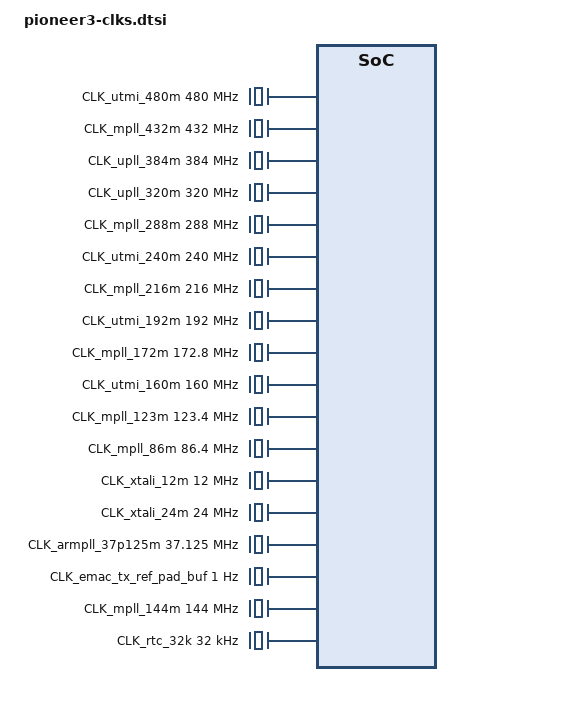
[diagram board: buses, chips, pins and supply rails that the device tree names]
/*
* pioneer3-clks.dtsi- Sigmastar
*
* Copyright (c) [2019~2020] SigmaStar Technology.
*
*
* This software is licensed under the terms of the GNU General Public
* License version 2, as published by the Free Software Foundation, and
* may be copied, distributed, and modified under those terms.
*
* This program is distributed in the hope that it will be useful,
* but WITHOUT ANY WARRANTY; without even the implied warranty of
* MERCHANTABILITY or FITNESS FOR A PARTICULAR PURPOSE.  See the
* GNU General Public License version 2 for more details.
*
*/

/* generated by CLK_DT_GEN_5.1 */
/* CLK FILENAME: Pioneer3\Pioneer3_Clock_Table_sw.xls */
/* REG FILENAME: Pioneer3\Pioneer3_reg_CLKGEN.xls, Pioneer3\Pioneer3_reg_pm_sleep.xls, Pioneer3\Pioneer3_reg_block.xls, Pioneer3\Pioneer3_reg_chiptop.xls */

CLK_VOID: CLK_VOID {
    #clock-cells = <0>;
    compatible = "fixed-clock";
    clock-frequency = <1>;
};

CLK_utmi_480m: CLK_utmi_480m {
    #clock-cells = <0>;
    compatible = "fixed-clock";
    clock-frequency = <480000000>;
};

CLK_mpll_432m: CLK_mpll_432m {
    #clock-cells = <0>;
    compatible = "fixed-clock";
    clock-frequency = <432000000>;
};

CLK_upll_384m: CLK_upll_384m {
    #clock-cells = <0>;
    compatible = "fixed-clock";
    clock-frequency = <384000000>;
};

CLK_upll_320m: CLK_upll_320m {
    #clock-cells = <0>;
    compatible = "fixed-clock";
    clock-frequency = <320000000>;
};

CLK_mpll_288m: CLK_mpll_288m {
    #clock-cells = <0>;
    compatible = "fixed-clock";
    clock-frequency = <288000000>;
};

CLK_utmi_240m: CLK_utmi_240m {
    #clock-cells = <0>;
    compatible = "fixed-clock";
    clock-frequency = <240000000>;
};

CLK_mpll_216m: CLK_mpll_216m {
    #clock-cells = <0>;
    compatible = "fixed-clock";
    clock-frequency = <216000000>;
};

CLK_utmi_192m: CLK_utmi_192m {
    #clock-cells = <0>;
    compatible = "fixed-clock";
    clock-frequency = <192000000>;
};

CLK_mpll_172m: CLK_mpll_172m {
    #clock-cells = <0>;
    compatible = "fixed-clock";
    clock-frequency = <172800000>;
};

CLK_utmi_160m: CLK_utmi_160m {
    #clock-cells = <0>;
    compatible = "fixed-clock";
    clock-frequency = <160000000>;
};

CLK_mpll_123m: CLK_mpll_123m {
    #clock-cells = <0>;
    compatible = "fixed-clock";
    clock-frequency = <123400000>;
};

CLK_mpll_86m: CLK_mpll_86m {
    #clock-cells = <0>;
    compatible = "fixed-clock";
    clock-frequency = <86400000>;
};

CLK_mpll_288m_div2: CLK_mpll_288m_div2 {
    #clock-cells = <0>;
    compatible = "fixed-factor-clock";
    clocks = <&CLK_mpll_288m>;
    clock-div = <2>;
    clock-mult = <1>;
};

CLK_mpll_288m_div4: CLK_mpll_288m_div4 {
    #clock-cells = <0>;
    compatible = "fixed-factor-clock";
    clocks = <&CLK_mpll_288m>;
    clock-div = <4>;
    clock-mult = <1>;
};

CLK_mpll_288m_div8: CLK_mpll_288m_div8 {
    #clock-cells = <0>;
    compatible = "fixed-factor-clock";
    clocks = <&CLK_mpll_288m>;
    clock-div = <8>;
    clock-mult = <1>;
};

CLK_mpll_288m_div32: CLK_mpll_288m_div32 {
    #clock-cells = <0>;
    compatible = "fixed-factor-clock";
    clocks = <&CLK_mpll_288m>;
    clock-div = <32>;
    clock-mult = <1>;
};

CLK_mpll_216m_div2: CLK_mpll_216m_div2 {
    #clock-cells = <0>;
    compatible = "fixed-factor-clock";
    clocks = <&CLK_mpll_216m>;
    clock-div = <2>;
    clock-mult = <1>;
};

CLK_mpll_216m_div4: CLK_mpll_216m_div4 {
    #clock-cells = <0>;
    compatible = "fixed-factor-clock";
    clocks = <&CLK_mpll_216m>;
    clock-div = <4>;
    clock-mult = <1>;
};

CLK_mpll_216m_div8: CLK_mpll_216m_div8 {
    #clock-cells = <0>;
    compatible = "fixed-factor-clock";
    clocks = <&CLK_mpll_216m>;
    clock-div = <8>;
    clock-mult = <1>;
};

CLK_mpll_123m_div2: CLK_mpll_123m_div2 {
    #clock-cells = <0>;
    compatible = "fixed-factor-clock";
    clocks = <&CLK_mpll_123m>;
    clock-div = <2>;
    clock-mult = <1>;
};

CLK_mpll_86m_div2: CLK_mpll_86m_div2 {
    #clock-cells = <0>;
    compatible = "fixed-factor-clock";
    clocks = <&CLK_mpll_86m>;
    clock-div = <2>;
    clock-mult = <1>;
};

CLK_mpll_86m_div4: CLK_mpll_86m_div4 {
    #clock-cells = <0>;
    compatible = "fixed-factor-clock";
    clocks = <&CLK_mpll_86m>;
    clock-div = <4>;
    clock-mult = <1>;
};

CLK_mpll_86m_div16: CLK_mpll_86m_div16 {
    #clock-cells = <0>;
    compatible = "fixed-factor-clock";
    clocks = <&CLK_mpll_86m>;
    clock-div = <16>;
    clock-mult = <1>;
};

CLK_utmi_192m_div4: CLK_utmi_192m_div4 {
    #clock-cells = <0>;
    compatible = "fixed-factor-clock";
    clocks = <&CLK_utmi_192m>;
    clock-div = <4>;
    clock-mult = <1>;
};

CLK_utmi_160m_div4: CLK_utmi_160m_div4 {
    #clock-cells = <0>;
    compatible = "fixed-factor-clock";
    clocks = <&CLK_utmi_160m>;
    clock-div = <4>;
    clock-mult = <1>;
};

CLK_utmi_160m_div5: CLK_utmi_160m_div5 {
    #clock-cells = <0>;
    compatible = "fixed-factor-clock";
    clocks = <&CLK_utmi_160m>;
    clock-div = <5>;
    clock-mult = <1>;
};

CLK_utmi_160m_div8: CLK_utmi_160m_div8 {
    #clock-cells = <0>;
    compatible = "fixed-factor-clock";
    clocks = <&CLK_utmi_160m>;
    clock-div = <8>;
    clock-mult = <1>;
};

CLK_xtali_12m: CLK_xtali_12m {
    #clock-cells = <0>;
    compatible = "fixed-clock";
    clock-frequency = <12000000>;
};

CLK_xtali_12m_div8: CLK_xtali_12m_div8 {
    #clock-cells = <0>;
    compatible = "fixed-factor-clock";
    clocks = <&CLK_xtali_12m>;
    clock-div = <8>;
    clock-mult = <1>;
};

CLK_xtali_12m_div16: CLK_xtali_12m_div16 {
    #clock-cells = <0>;
    compatible = "fixed-factor-clock";
    clocks = <&CLK_xtali_12m>;
    clock-div = <16>;
    clock-mult = <1>;
};

CLK_xtali_12m_div40: CLK_xtali_12m_div40 {
    #clock-cells = <0>;
    compatible = "fixed-factor-clock";
    clocks = <&CLK_xtali_12m>;
    clock-div = <40>;
    clock-mult = <1>;
};

CLK_xtali_12m_div64: CLK_xtali_12m_div64 {
    #clock-cells = <0>;
    compatible = "fixed-factor-clock";
    clocks = <&CLK_xtali_12m>;
    clock-div = <64>;
    clock-mult = <1>;
};

CLK_xtali_12m_div128: CLK_xtali_12m_div128 {
    #clock-cells = <0>;
    compatible = "fixed-factor-clock";
    clocks = <&CLK_xtali_12m>;
    clock-div = <128>;
    clock-mult = <1>;
};

CLK_xtali_24m: CLK_xtali_24m {
    #clock-cells = <0>;
    compatible = "fixed-clock";
    clock-frequency = <24000000>;
};

CLK_lpll_clk: CLK_lpll_clk {
    #clock-cells = <0>;
    compatible = "fixed-clock";
    clock-frequency = <288000000>;
};

CLK_lpll_clk_div2: CLK_lpll_clk_div2 {
    #clock-cells = <0>;
    compatible = "fixed-factor-clock";
    clocks = <&CLK_lpll_clk>;
    clock-div = <2>;
    clock-mult = <1>;
};

CLK_lpll_clk_div4: CLK_lpll_clk_div4 {
    #clock-cells = <0>;
    compatible = "fixed-factor-clock";
    clocks = <&CLK_lpll_clk>;
    clock-div = <4>;
    clock-mult = <1>;
};

CLK_lpll_clk_div8: CLK_lpll_clk_div8 {
    #clock-cells = <0>;
    compatible = "fixed-factor-clock";
    clocks = <&CLK_lpll_clk>;
    clock-div = <8>;
    clock-mult = <1>;
};

CLK_spi_synth_pll: CLK_spi_synth_pll {
    #clock-cells = <0>;
    compatible = "fixed-clock";
    clock-frequency = <104000000>;
};

CLK_fuart0_synth_out: CLK_fuart0_synth_out {
    #clock-cells = <0>;
    compatible = "fixed-clock";
    clock-frequency = <432000000>;
};

CLK_miu_p: CLK_miu_p {
    #clock-cells = <0>;
    compatible = "fixed-clock";
    clock-frequency = <266000000>;
};

CLK_mcu_p: CLK_mcu_p {
    #clock-cells = <0>;
    compatible = "fixed-clock";
    clock-frequency = <432000000>;
};

CLK_emac_testrx125_in_lan: CLK_emac_testrx125_in_lan {
    #clock-cells = <0>;
    compatible = "fixed-clock";
    clock-frequency = <125000000>;
};

CLK_armpll_37p125m: CLK_armpll_37p125m {
    #clock-cells = <0>;
    compatible = "fixed-clock";
    clock-frequency = <37125000>;
};

CLK_boot: CLK_boot {
    #clock-cells = <0>;
    compatible = "fixed-clock";
    clock-frequency = <12000000>;
};

CLK_dac_in: CLK_dac_in {
    #clock-cells = <0>;
    compatible = "fixed-clock";
    clock-frequency = <1>;
};

CLK_hdmi_p: CLK_hdmi_p {
    #clock-cells = <0>;
    compatible = "fixed-clock";
    clock-frequency = <1>;
};

CLK_emac_rx_in_buf: CLK_emac_rx_in_buf {
    #clock-cells = <0>;
    compatible = "fixed-clock";
    clock-frequency = <1>;
};

CLK_emac_mmi_rx_buf: CLK_emac_mmi_rx_buf {
    #clock-cells = <0>;
    compatible = "fixed-clock";
    clock-frequency = <1>;
};

CLK_emac_tx_ref_pad_buf: CLK_emac_tx_ref_pad_buf {
    #clock-cells = <0>;
    compatible = "fixed-clock";
    clock-frequency = <1>;
};

CLK_emac_tx_in_buf: CLK_emac_tx_in_buf {
    #clock-cells = <0>;
    compatible = "fixed-clock";
    clock-frequency = <1>;
};

CLK_emac_mmi_tx_buf: CLK_emac_mmi_tx_buf {
    #clock-cells = <0>;
    compatible = "fixed-clock";
    clock-frequency = <1>;
};

CLK_odclk_live_p: CLK_odclk_live_p {
    #clock-cells = <0>;
    compatible = "fixed-clock";
    clock-frequency = <1>;
};

CLK_miu_gop0_p: CLK_miu_gop0_p {
    #clock-cells = <0>;
    compatible = "fixed-clock";
    clock-frequency = <1>;
};

CLK_miu_gop1_p: CLK_miu_gop1_p {
    #clock-cells = <0>;
    compatible = "fixed-clock";
    clock-frequency = <1>;
};

CLK_sc_pixel_p: CLK_sc_pixel_p {
    #clock-cells = <0>;
    compatible = "fixed-clock";
    clock-frequency = <1>;
};

CLK_mipi_tx_dsi_p: CLK_mipi_tx_dsi_p {
    #clock-cells = <0>;
    compatible = "fixed-clock";
    clock-frequency = <1>;
};

CLK_miu_sc_gp_p_inv: CLK_miu_sc_gp_p_inv {
    #clock-cells = <0>;
    compatible = "fixed-clock";
    clock-frequency = <1>;
};

CLK_pad_sdio_clk_mux: CLK_pad_sdio_clk_mux {
    #clock-cells = <0>;
    compatible = "fixed-clock";
    clock-frequency = <1>;
};

CLK_mpll_144m: CLK_mpll_144m {
    #clock-cells = <0>;
    compatible = "fixed-clock";
    clock-frequency = <144000000>;
};

CLK_mpll_144m_div2: CLK_mpll_144m_div2 {
    #clock-cells = <0>;
    compatible = "fixed-factor-clock";
    clocks = <&CLK_mpll_144m>;
    clock-div = <2>;
    clock-mult = <1>;
};

CLK_mpll_144m_div4: CLK_mpll_144m_div4 {
    #clock-cells = <0>;
    compatible = "fixed-factor-clock";
    clocks = <&CLK_mpll_144m>;
    clock-div = <4>;
    clock-mult = <1>;
};

CLK_xtali_12m_div2: CLK_xtali_12m_div2 {
    #clock-cells = <0>;
    compatible = "fixed-factor-clock";
    clocks = <&CLK_xtali_12m>;
    clock-div = <2>;
    clock-mult = <1>;
};

CLK_xtali_12m_div4: CLK_xtali_12m_div4 {
    #clock-cells = <0>;
    compatible = "fixed-factor-clock";
    clocks = <&CLK_xtali_12m>;
    clock-div = <4>;
    clock-mult = <1>;
};

CLK_xtali_12m_div12: CLK_xtali_12m_div12 {
    #clock-cells = <0>;
    compatible = "fixed-factor-clock";
    clocks = <&CLK_xtali_12m>;
    clock-div = <12>;
    clock-mult = <1>;
};

CLK_rtc_32k: CLK_rtc_32k {
    #clock-cells = <0>;
    compatible = "fixed-clock";
    clock-frequency = <32000>;
};

CLK_rtc_32k_div4: CLK_rtc_32k_div4 {
    #clock-cells = <0>;
    compatible = "fixed-factor-clock";
    clocks = <&CLK_rtc_32k>;
    clock-div = <4>;
    clock-mult = <1>;
};

CLK_ddr_syn: CLK_ddr_syn {
    #clock-cells = <0>;
    compatible = "sstar,composite-clock";
    clocks = <&CLK_mpll_432m>,<&CLK_mpll_216m>,<&CLK_xtali_12m>,<&CLK_VOID>;
    reg = <REG_CKG_DDR_SYN_BASE 0x4>;
    mux-shift = <2>;  //2+REG_CKG_DDR_SYN_OFFSET
    mux-width = <2>;
    gate-shift = <0>;  //0+REG_CKG_DDR_SYN_OFFSET
    auto-enable = <1>;
};

CLK_miu_rec: CLK_miu_rec {
    #clock-cells = <0>;
    compatible = "sstar,composite-clock";
    clocks = <&CLK_xtali_12m_div8>,<&CLK_xtali_12m_div16>,<&CLK_xtali_12m_div64>,<&CLK_xtali_12m_div128>;
    reg = <REG_CKG_MIU_REC_BASE 0x4>;
    mux-shift = <2>;  //2+REG_CKG_MIU_REC_OFFSET
    mux-width = <2>;
    gate-shift = <0>;  //0+REG_CKG_MIU_REC_OFFSET
};

CLK_mcu: CLK_mcu {
    #clock-cells = <0>;
    compatible = "sstar,composite-clock";
    clocks = <&CLK_mpll_216m>,<&CLK_mpll_172m>,<&CLK_mpll_288m_div2>,<&CLK_mpll_216m_div4>,<&CLK_mpll_432m>,<&CLK_upll_384m>,<&CLK_upll_320m>,<&CLK_mpll_216m_div2>;
    reg = <REG_CKG_MCU_BASE 0x4>;
    mux-shift = <2>;  //2+REG_CKG_MCU_OFFSET
    mux-width = <3>;
    gate-shift = <0>;  //0+REG_CKG_MCU_OFFSET
    glitch-shift = <5>;  //5+REG_CKG_MCU_OFFSET
#ifdef CONFIG_CAM_CLK
        ignore = <1>;
#endif
    auto-enable = <1>;
};

CLK_riubrdg: CLK_riubrdg {
    #clock-cells = <0>;
    compatible = "sstar,composite-clock";
    clocks = <&CLK_mcu_p>,<&CLK_VOID>,<&CLK_VOID>,<&CLK_VOID>;
    reg = <REG_CKG_RIUBRDG_BASE 0x4>;
    mux-shift = <10>;  //2+REG_CKG_RIUBRDG_OFFSET
    mux-width = <2>;
    gate-shift = <8>;  //0+REG_CKG_RIUBRDG_OFFSET
    auto-enable = <1>;
};

CLK_bdma: CLK_bdma {
    #clock-cells = <0>;
    compatible = "sstar,composite-clock";
    clocks = <&CLK_miu_p>,<&CLK_VOID>,<&CLK_VOID>,<&CLK_VOID>;
    reg = <REG_CKG_BDMA_BASE 0x4>;
    mux-shift = <2>;  //2+REG_CKG_BDMA_OFFSET
    mux-width = <2>;
    gate-shift = <0>;  //0+REG_CKG_BDMA_OFFSET
    glitch-shift = <4>;  //4+REG_CKG_BDMA_OFFSET
#ifdef CONFIG_CAM_CLK
        ignore = <1>;
#endif
};

CLK_bdma2: CLK_bdma2 {
    #clock-cells = <0>;
    compatible = "sstar,composite-clock";
    clocks = <&CLK_miu_p>,<&CLK_VOID>,<&CLK_VOID>,<&CLK_VOID>;
    reg = <REG_CKG_BDMA2_BASE 0x4>;
    mux-shift = <10>;  //2+REG_CKG_BDMA2_OFFSET
    mux-width = <2>;
    gate-shift = <8>;  //0+REG_CKG_BDMA2_OFFSET
#ifdef CONFIG_CAM_CLK
        ignore = <1>;
#endif
};

CLK_bdma3: CLK_bdma3 {
    #clock-cells = <0>;
    compatible = "sstar,composite-clock";
    clocks = <&CLK_miu_p>,<&CLK_VOID>,<&CLK_VOID>,<&CLK_VOID>;
    reg = <REG_CKG_BDMA3_BASE 0x4>;
    mux-shift = <14>;  //2+REG_CKG_BDMA3_OFFSET
    mux-width = <2>;
    gate-shift = <12>;  //0+REG_CKG_BDMA3_OFFSET
#ifdef CONFIG_CAM_CLK
        ignore = <1>;
#endif
};

CLK_spi: CLK_spi {
    #clock-cells = <0>;
    compatible = "sstar,composite-clock";
    clocks = <&CLK_mpll_216m>,<&CLK_mpll_216m_div2>,<&CLK_mpll_86m>,<&CLK_mpll_288m_div4>,<&CLK_miu_p>,<&CLK_VOID>,<&CLK_VOID>,<&CLK_VOID>;
    reg = <REG_CKG_SPI_BASE 0x4>;
    mux-shift = <2>;  //2+REG_CKG_SPI_OFFSET
    mux-width = <3>;
    gate-shift = <0>;  //0+REG_CKG_SPI_OFFSET
    auto-enable = <1>;
};

CLK_uart0: CLK_uart0 {
    #clock-cells = <0>;
    compatible = "sstar,composite-clock";
    clocks = <&CLK_mpll_172m>,<&CLK_mpll_288m_div2>,<&CLK_xtali_12m>,<&CLK_VOID>;
    reg = <REG_CKG_UART0_BASE 0x4>;
    mux-shift = <2>;  //2+REG_CKG_UART0_OFFSET
    mux-width = <2>;
    gate-shift = <0>;  //0+REG_CKG_UART0_OFFSET
 #ifdef CONFIG_CAM_CLK
    ignore = <1>;
#endif
};

CLK_uart1: CLK_uart1 {
    #clock-cells = <0>;
    compatible = "sstar,composite-clock";
    clocks = <&CLK_mpll_172m>,<&CLK_mpll_288m_div2>,<&CLK_xtali_12m>,<&CLK_VOID>;
    reg = <REG_CKG_UART1_BASE 0x4>;
    mux-shift = <10>;  //2+REG_CKG_UART1_OFFSET
    mux-width = <2>;
    gate-shift = <8>;  //0+REG_CKG_UART1_OFFSET
#ifdef CONFIG_CAM_CLK
    ignore = <1>;
#endif
};

CLK_uart2: CLK_uart2 {
    #clock-cells = <0>;
    compatible = "sstar,composite-clock";
    clocks = <&CLK_mpll_172m>,<&CLK_mpll_288m_div2>,<&CLK_xtali_12m>,<&CLK_VOID>;
    reg = <REG_CKG_UART2_BASE 0x4>;
    mux-shift = <14>;  //2+REG_CKG_UART2_OFFSET
    mux-width = <2>;
    gate-shift = <12>;  //0+REG_CKG_UART2_OFFSET
#ifdef CONFIG_CAM_CLK
    ignore = <1>;
#endif
};

CLK_fuart0_synth_in: CLK_fuart0_synth_in {
    #clock-cells = <0>;
    compatible = "sstar,composite-clock";
    clocks = <&CLK_mpll_432m>,<&CLK_mpll_216m>,<&CLK_VOID>,<&CLK_VOID>;
    reg = <REG_CKG_FUART0_SYNTH_IN_BASE 0x4>;
    mux-shift = <6>;  //2+REG_CKG_FUART0_SYNTH_IN_OFFSET
    mux-width = <2>;
    gate-shift = <4>;  //0+REG_CKG_FUART0_SYNTH_IN_OFFSET
};

CLK_fuart: CLK_fuart {
    #clock-cells = <0>;
    compatible = "sstar,composite-clock";
    clocks = <&CLK_mpll_172m>,<&CLK_mpll_288m_div2>,<&CLK_xtali_12m>,<&CLK_fuart0_synth_out>;
    reg = <REG_CKG_FUART_BASE 0x4>;
    mux-shift = <2>;  //2+REG_CKG_FUART_OFFSET
    mux-width = <2>;
    gate-shift = <0>;  //0+REG_CKG_FUART_OFFSET
#ifdef CONFIG_CAM_CLK
    ignore = <1>;
#endif
};

CLK_mspi0: CLK_mspi0 {
    #clock-cells = <0>;
    compatible = "sstar,composite-clock";
    clocks = <&CLK_mpll_216m_div2>,<&CLK_spi_synth_pll>,<&CLK_xtali_12m>,<&CLK_mpll_288m_div2>;
    reg = <REG_CKG_MSPI0_BASE 0x4>;
    mux-shift = <2>;  //2+REG_CKG_MSPI0_OFFSET
    mux-width = <2>;
    gate-shift = <0>;  //0+REG_CKG_MSPI0_OFFSET
#ifdef CONFIG_CAM_CLK
    ignore = <1>;
#endif
};

CLK_mspi1: CLK_mspi1 {
    #clock-cells = <0>;
    compatible = "sstar,composite-clock";
    clocks = <&CLK_mpll_216m_div2>,<&CLK_spi_synth_pll>,<&CLK_xtali_12m>,<&CLK_mpll_288m_div2>;
    reg = <REG_CKG_MSPI1_BASE 0x4>;
    mux-shift = <10>;  //2+REG_CKG_MSPI1_OFFSET
    mux-width = <2>;
    gate-shift = <8>;  //0+REG_CKG_MSPI1_OFFSET
#ifdef CONFIG_CAM_CLK
    ignore = <1>;
#endif
};

CLK_miic0: CLK_miic0 {
    #clock-cells = <0>;
    compatible = "sstar,composite-clock";
    clocks = <&CLK_mpll_288m_div4>,<&CLK_mpll_216m_div4>,<&CLK_xtali_12m>,<&CLK_VOID>;
    reg = <REG_CKG_MIIC0_BASE 0x4>;
    mux-shift = <2>;  //2+REG_CKG_MIIC0_OFFSET
    mux-width = <2>;
    gate-shift = <0>;  //0+REG_CKG_MIIC0_OFFSET
#ifdef CONFIG_CAM_CLK
    ignore = <1>;
#endif
};

CLK_miic1: CLK_miic1 {
    #clock-cells = <0>;
    compatible = "sstar,composite-clock";
    clocks = <&CLK_mpll_288m_div4>,<&CLK_mpll_216m_div4>,<&CLK_xtali_12m>,<&CLK_VOID>;
    reg = <REG_CKG_MIIC1_BASE 0x4>;
    mux-shift = <10>;  //2+REG_CKG_MIIC1_OFFSET
    mux-width = <2>;
    gate-shift = <8>;  //0+REG_CKG_MIIC1_OFFSET
#ifdef CONFIG_CAM_CLK
    ignore = <1>;
#endif
};

CLK_keypad: CLK_keypad {
    #clock-cells = <0>;
    compatible = "sstar,composite-clock";
    clocks = <&CLK_xtali_12m>,<&CLK_VOID>,<&CLK_VOID>,<&CLK_VOID>;
    reg = <REG_CKG_KEYPAD_BASE 0x4>;
    mux-shift = <2>;  //2+REG_CKG_KEYPAD_OFFSET
    mux-width = <2>;
    gate-shift = <0>;  //0+REG_CKG_KEYPAD_OFFSET
#ifdef CONFIG_CAM_CLK
    ignore = <1>;
#endif
};

CLK_bist: CLK_bist {
    #clock-cells = <0>;
    compatible = "sstar,composite-clock";
    clocks = <&CLK_mpll_172m>,<&CLK_mpll_216m_div2>,<&CLK_mpll_216m_div4>,<&CLK_xtali_12m>;
    reg = <REG_CKG_BIST_BASE 0x4>;
    mux-shift = <2>;  //2+REG_CKG_BIST_OFFSET
    mux-width = <2>;
    gate-shift = <0>;  //0+REG_CKG_BIST_OFFSET
};

CLK_pwr_ctl: CLK_pwr_ctl {
    #clock-cells = <0>;
    compatible = "sstar,composite-clock";
    clocks = <&CLK_xtali_12m_div16>,<&CLK_xtali_12m_div8>,<&CLK_xtali_12m>,<&CLK_VOID>;
    reg = <REG_CKG_PWR_CTL_BASE 0x4>;
    mux-shift = <2>;  //2+REG_CKG_PWR_CTL_OFFSET
    mux-width = <2>;
    gate-shift = <0>;  //0+REG_CKG_PWR_CTL_OFFSET
};

CLK_xtali: CLK_xtali {
    #clock-cells = <0>;
    compatible = "sstar,composite-clock";
    clocks = <&CLK_xtali_12m>,<&CLK_VOID>,<&CLK_VOID>,<&CLK_VOID>;
    reg = <REG_CKG_XTALI_BASE 0x4>;
    mux-shift = <2>;  //2+REG_CKG_XTALI_OFFSET
    mux-width = <2>;
    gate-shift = <0>;  //0+REG_CKG_XTALI_OFFSET
    auto-enable = <1>;
};

CLK_bach: CLK_bach {
    #clock-cells = <0>;
    compatible = "sstar,composite-clock";
    clocks = <&CLK_upll_384m>;
    reg = <REG_CKG_BACH_384M_BASE 0x4>;
    //mux-shift = <2>;  //2+REG_CKG_MIU_OFFSET
    //mux-width = <2>;
    gate-shift = <7>;  //0+REG_CKG_MIU_OFFSET
    //glitch-shift = <4>;  //4+REG_CKG_MIU_OFFSET
    //auto-enable = <0>;
};

CLK_live_c: CLK_live_c {
    #clock-cells = <0>;
    compatible = "sstar,composite-clock";
    clocks = <&CLK_xtali_12m>,<&CLK_VOID>,<&CLK_VOID>,<&CLK_VOID>;
    reg = <REG_CKG_LIVE_BASE 0x4>;
    mux-shift = <10>;  //2+REG_CKG_LIVE_OFFSET
    mux-width = <2>;
    gate-shift = <8>;  //0+REG_CKG_LIVE_OFFSET
    auto-enable = <1>;
};

CLK_live: CLK_live {
    #clock-cells = <0>;
    compatible = "sstar,composite-clock";
    clocks = <&CLK_xtali_12m>,<&CLK_VOID>,<&CLK_VOID>,<&CLK_VOID>;
    reg = <REG_CKG_LIVE_BASE 0x4>;
    mux-shift = <10>;  //2+REG_CKG_LIVE_OFFSET
    mux-width = <2>;
    gate-shift = <8>;  //0+REG_CKG_LIVE_OFFSET
    auto-enable = <1>;
};

CLK_sr00_mclk: CLK_sr00_mclk {
    #clock-cells = <0>;
    compatible = "sstar,composite-clock";
    clocks = <&CLK_mpll_216m_div8>,<&CLK_mpll_288m_div4>,<&CLK_mpll_123m_div2>,<&CLK_mpll_216m_div4>,<&CLK_utmi_192m_div4>,<&CLK_mpll_86m_div2>,<&CLK_mpll_288m_div8>,<&CLK_xtali_24m>,<&CLK_mpll_86m_div4>,<&CLK_xtali_12m>,<&CLK_mpll_86m_div16>,<&CLK_lpll_clk>,<&CLK_lpll_clk_div2>,<&CLK_lpll_clk_div4>,<&CLK_lpll_clk_div8>,<&CLK_armpll_37p125m>;
    reg = <REG_CKG_SR00_MCLK_BASE 0x4>;
    mux-shift = <10>;  //2+REG_CKG_SR00_MCLK_OFFSET
    mux-width = <4>;
    gate-shift = <8>;  //0+REG_CKG_SR00_MCLK_OFFSET
};

CLK_sr01_mclk: CLK_sr01_mclk {
    #clock-cells = <0>;
    compatible = "sstar,composite-clock";
    clocks = <&CLK_mpll_216m_div8>,<&CLK_mpll_288m_div4>,<&CLK_mpll_123m_div2>,<&CLK_mpll_216m_div4>,<&CLK_utmi_192m_div4>,<&CLK_mpll_86m_div2>,<&CLK_mpll_288m_div8>,<&CLK_xtali_24m>,<&CLK_mpll_86m_div4>,<&CLK_xtali_12m>,<&CLK_mpll_86m_div16>,<&CLK_lpll_clk>,<&CLK_lpll_clk_div2>,<&CLK_lpll_clk_div4>,<&CLK_lpll_clk_div8>,<&CLK_armpll_37p125m>;
    reg = <REG_CKG_SR01_MCLK_BASE 0x4>;
    mux-shift = <2>;  //2+REG_CKG_SR01_MCLK_OFFSET
    mux-width = <4>;
    gate-shift = <0>;  //0+REG_CKG_SR01_MCLK_OFFSET
};

CLK_sata_phy_108: CLK_sata_phy_108 {
    #clock-cells = <0>;
    compatible = "sstar,composite-clock";
    clocks = <&CLK_mpll_216m_div2>,<&CLK_VOID>,<&CLK_VOID>,<&CLK_VOID>;
    reg = <REG_CKG_SATA_PHY_108_BASE 0x4>;
    mux-shift = <2>;  //2+REG_CKG_SATA_PHY_108_OFFSET
    mux-width = <2>;
    gate-shift = <0>;  //0+REG_CKG_SATA_PHY_108_OFFSET
#ifdef CONFIG_CAM_CLK
        ignore = <1>;
#endif
};

CLK_sata_phy_432: CLK_sata_phy_432 {
    #clock-cells = <0>;
    compatible = "sstar,composite-clock";
    clocks = <&CLK_mpll_432m>,<&CLK_VOID>,<&CLK_VOID>,<&CLK_VOID>;
    reg = <REG_CKG_SATA_PHY_432_BASE 0x4>;
    mux-shift = <10>;  //2+REG_CKG_SATA_PHY_432_OFFSET
    mux-width = <2>;
    gate-shift = <8>;  //0+REG_CKG_SATA_PHY_432_OFFSET
#ifdef CONFIG_CAM_CLK
        ignore = <1>;
#endif
};

CLK_disp_432: CLK_disp_432 {
    #clock-cells = <0>;
    compatible = "sstar,composite-clock";
    clocks = <&CLK_mpll_432m>,<&CLK_VOID>,<&CLK_VOID>,<&CLK_VOID>;
    reg = <REG_CKG_DISP_432_BASE 0x4>;
    mux-shift = <2>;  //2+REG_CKG_DISP_432_OFFSET
    mux-width = <2>;
    gate-shift = <0>;  //0+REG_CKG_DISP_432_OFFSET
#ifdef CONFIG_CAM_CLK
        ignore = <1>;
#endif
    auto-enable = <1>;
};

CLK_pspi0: CLK_pspi0 {
    #clock-cells = <0>;
    compatible = "sstar,composite-clock";
    clocks = <&CLK_mpll_216m>,<&CLK_utmi_192m>,<&CLK_mpll_172m>,<&CLK_mpll_288m_div2>,<&CLK_spi_synth_pll>,<&CLK_mpll_86m>,<&CLK_xtali_24m>,<&CLK_xtali_12m>;
    reg = <REG_CKG_PSPI0_BASE 0x4>;
    mux-shift = <2>;  //2+REG_CKG_PSPI0_OFFSET
    mux-width = <3>;
    gate-shift = <0>;  //0+REG_CKG_PSPI0_OFFSET
#ifdef CONFIG_CAM_CLK
        ignore = <1>;
#endif
};

CLK_pspi1: CLK_pspi1 {
    #clock-cells = <0>;
    compatible = "sstar,composite-clock";
    clocks = <&CLK_mpll_216m>,<&CLK_utmi_192m>,<&CLK_mpll_172m>,<&CLK_mpll_288m_div2>,<&CLK_spi_synth_pll>,<&CLK_mpll_86m>,<&CLK_xtali_24m>,<&CLK_xtali_12m>;
    reg = <REG_CKG_PSPI1_BASE 0x4>;
    mux-shift = <10>;  //2+REG_CKG_PSPI1_OFFSET
    mux-width = <3>;
    gate-shift = <8>;  //0+REG_CKG_PSPI1_OFFSET
#ifdef CONFIG_CAM_CLK
        ignore = <1>;
#endif
};

CLK_upll_synth: CLK_upll_synth {
    #clock-cells = <0>;
    compatible = "sstar,composite-clock";
    clocks = <&CLK_mpll_216m>,<&CLK_mpll_432m>,<&CLK_VOID>,<&CLK_VOID>;
    reg = <REG_CKG_UPLL_SYNTH_BASE 0x4>;
    mux-shift = <2>;  //2+REG_CKG_UPLL_SYNTH_OFFSET
    mux-width = <2>;
    gate-shift = <0>;  //0+REG_CKG_UPLL_SYNTH_OFFSET
};

CLK_xtali_sc_gp: CLK_xtali_sc_gp {
    #clock-cells = <0>;
    compatible = "sstar,composite-clock";
    clocks = <&CLK_xtali_12m>,<&CLK_VOID>,<&CLK_VOID>,<&CLK_VOID>;
    reg = <REG_CKG_XTALI_SC_GP_BASE 0x4>;
    mux-shift = <6>;  //2+REG_CKG_XTALI_SC_GP_OFFSET
    mux-width = <2>;
    gate-shift = <4>;  //0+REG_CKG_XTALI_SC_GP_OFFSET
};

CLK_bist_sc_gp: CLK_bist_sc_gp {
    #clock-cells = <0>;
    compatible = "sstar,composite-clock";
    clocks = <&CLK_mpll_172m>,<&CLK_mpll_216m_div2>,<&CLK_mpll_216m_div4>,<&CLK_xtali_12m>;
    reg = <REG_CKG_BIST_SC_GP_BASE 0x4>;
    mux-shift = <2>;  //2+REG_CKG_BIST_SC_GP_OFFSET
    mux-width = <2>;
    gate-shift = <0>;  //0+REG_CKG_BIST_SC_GP_OFFSET
};

CLK_bist_isp_gp: CLK_bist_isp_gp {
    #clock-cells = <0>;
    compatible = "sstar,composite-clock";
    clocks = <&CLK_mpll_172m>,<&CLK_mpll_216m_div2>,<&CLK_mpll_216m_div4>,<&CLK_xtali_12m>;
    reg = <REG_CKG_BIST_ISP_GP_BASE 0x4>;
    mux-shift = <6>;  //2+REG_CKG_BIST_ISP_GP_OFFSET
    mux-width = <2>;
    gate-shift = <4>;  //0+REG_CKG_BIST_ISP_GP_OFFSET
};

CLK_bist_mcu: CLK_bist_mcu {
    #clock-cells = <0>;
    compatible = "sstar,composite-clock";
    clocks = <&CLK_mpll_288m>,<&CLK_mpll_216m>,<&CLK_mpll_172m>,<&CLK_mpll_216m_div2>,<&CLK_mpll_86m>,<&CLK_mpll_216m_div4>,<&CLK_mpll_216m_div8>,<&CLK_xtali_12m>;
    reg = <REG_CKG_BIST_MCU_BASE 0x4>;
    mux-shift = <2>;  //2+REG_CKG_BIST_MCU_OFFSET
    mux-width = <3>;
    gate-shift = <0>;  //0+REG_CKG_BIST_MCU_OFFSET
};

CLK_emac_ahb: CLK_emac_ahb {
    #clock-cells = <0>;
    compatible = "sstar,composite-clock";
    clocks = <&CLK_mpll_288m_div2>,<&CLK_mpll_123m>,<&CLK_mpll_86m>,<&CLK_emac_testrx125_in_lan>;
    reg = <REG_CKG_EMAC_AHB_BASE 0x4>;
    mux-shift = <2>;  //2+REG_CKG_EMAC_AHB_OFFSET
    mux-width = <2>;
    gate-shift = <0>;  //0+REG_CKG_EMAC_AHB_OFFSET
#ifdef CONFIG_CAM_CLK
    ignore = <1>;
#endif
};

CLK_jpe: CLK_jpe {
    #clock-cells = <0>;
    compatible = "sstar,composite-clock";
    clocks = <&CLK_mpll_172m>,<&CLK_mpll_288m_div2>,<&CLK_VOID>,<&CLK_VOID>,<&CLK_VOID>,<&CLK_mpll_216m>,<&CLK_VOID>,<&CLK_VOID>;
    reg = <REG_CKG_JPE_BASE 0x4>;
    mux-shift = <2>;  //2+REG_CKG_JPE_OFFSET
    mux-width = <3>;
    gate-shift = <0>;  //0+REG_CKG_JPE_OFFSET
};

CLK_aesdma: CLK_aesdma {
    #clock-cells = <0>;
    compatible = "sstar,composite-clock";
    clocks = <&CLK_mpll_86m>,<&CLK_mpll_172m>,<&CLK_mpll_216m>,<&CLK_mpll_288m>;
    reg = <REG_CKG_AESDMA_BASE 0x4>;
    mux-shift = <2>;  //2+REG_CKG_AESDMA_OFFSET
    mux-width = <2>;
    gate-shift = <0>;  //0+REG_CKG_AESDMA_OFFSET
    glitch-shift = <4>;  //4+REG_CKG_AESDMA_OFFSET
};

CLK_sdio: CLK_sdio {
    #clock-cells = <0>;
    compatible = "sstar,composite-clock";
    clocks = <&CLK_utmi_192m_div4>,<&CLK_mpll_86m_div2>,<&CLK_utmi_160m_div4>,<&CLK_mpll_288m_div8>,<&CLK_utmi_160m_div5>,<&CLK_utmi_160m_div8>,<&CLK_xtali_12m>,<&CLK_xtali_12m_div40>,<&CLK_spi_synth_pll>,<&CLK_mpll_432m>,<&CLK_upll_384m>,<&CLK_upll_320m>,<&CLK_mpll_288m>,<&CLK_mpll_216m>,<&CLK_mpll_216m_div2>,<&CLK_mpll_86m>;
    reg = <REG_CKG_SDIO_BASE 0x4>;
    mux-shift = <2>;  //2+REG_CKG_SDIO_OFFSET
    mux-width = <4>;
    gate-shift = <0>;  //0+REG_CKG_SDIO_OFFSET
};

CLK_isp: CLK_isp {
    #clock-cells = <0>;
    compatible = "sstar,composite-clock";
    clocks = <&CLK_mpll_123m>,<&CLK_mpll_86m>,<&CLK_mpll_288m_div2>,<&CLK_mpll_172m>,<&CLK_VOID>,<&CLK_VOID>,<&CLK_VOID>,<&CLK_VOID>;
    reg = <REG_CKG_ISP_BASE 0x4>;
    mux-shift = <10>;  //2+REG_CKG_ISP_OFFSET
    mux-width = <3>;
    gate-shift = <8>;  //0+REG_CKG_ISP_OFFSET
#ifdef CONFIG_CAM_CLK
        ignore = <1>;
#endif
};

CLK_fclk1: CLK_fclk1 {
    #clock-cells = <0>;
    compatible = "sstar,composite-clock";
    clocks = <&CLK_mpll_172m>,<&CLK_mpll_216m>,<&CLK_mpll_123m>,<&CLK_mpll_86m>;
    reg = <REG_CKG_FCLK1_BASE 0x4>;
    mux-shift = <2>;  //2+REG_CKG_FCLK1_OFFSET
    mux-width = <2>;
    gate-shift = <0>;  //0+REG_CKG_FCLK1_OFFSET
};

CLK_dip: CLK_dip {
    #clock-cells = <0>;
    compatible = "sstar,composite-clock";
    clocks = <&CLK_upll_320m>,<&CLK_upll_384m>,<&CLK_mpll_216m>,<&CLK_utmi_192m>,<&CLK_mpll_172m>,<&CLK_utmi_160m>,<&CLK_VOID>,<&CLK_VOID>;
    reg = <REG_CKG_DIP_BASE 0x4>;
    mux-shift = <2>;  //2+REG_CKG_DIP_OFFSET
    mux-width = <3>;
#ifdef CONFIG_CAM_CLK
        ignore = <1>;
#endif
    gate-shift = <0>;  //0+REG_CKG_DIP_OFFSET
};

CLK_ge: CLK_ge {
    #clock-cells = <0>;
    compatible = "sstar,composite-clock";
    clocks = <&CLK_miu_p>,<&CLK_mpll_216m>,<&CLK_mpll_172m>,<&CLK_mpll_288m>,<&CLK_VOID>,<&CLK_VOID>,<&CLK_VOID>,<&CLK_VOID>;
    reg = <REG_CKG_GE_BASE 0x4>;
    mux-shift = <2>;  //2+REG_CKG_GE_OFFSET
    mux-width = <3>;
    gate-shift = <0>;  //0+REG_CKG_GE_OFFSET
#ifdef CONFIG_CAM_CLK
        ignore = <1>;
#endif
};

CLK_mop: CLK_mop {
    #clock-cells = <0>;
    compatible = "sstar,composite-clock";
    clocks = <&CLK_upll_320m>,<&CLK_upll_384m>,<&CLK_mpll_288m>,<&CLK_utmi_240m>;
    reg = <REG_CKG_MOP_BASE 0x4>;
    mux-shift = <2>;  //2+REG_CKG_MOP_OFFSET
    mux-width = <2>;
    gate-shift = <0>;  //0+REG_CKG_MOP_OFFSET
#ifdef CONFIG_CAM_CLK
        ignore = <1>;
#endif
    auto-enable = <1>;
};

CLK_disp_216: CLK_disp_216 {
    #clock-cells = <0>;
    compatible = "sstar,composite-clock";
    clocks = <&CLK_mpll_216m>,<&CLK_mpll_216m_div2>;
    reg = <REG_CKG_DISP_216_BASE 0x4>;
    mux-shift = <10>;  //2+REG_CKG_DISP_216_OFFSET
    mux-width = <1>;
    gate-shift = <8>;  //0+REG_CKG_DISP_216_OFFSET
#ifdef CONFIG_CAM_CLK
        ignore = <1>;
#endif
    auto-enable = <1>;
};

CLK_sc_pixel: CLK_sc_pixel {
    #clock-cells = <0>;
    compatible = "sstar,composite-clock";
    clocks = <&CLK_mpll_172m>,<&CLK_utmi_192m>,<&CLK_mpll_123m>,<&CLK_mpll_288m_div2>,<&CLK_mpll_288m_div8>,<&CLK_mpll_216m_div4>,<&CLK_lpll_clk>,<&CLK_spi_synth_pll>,<&CLK_VOID>,<&CLK_VOID>,<&CLK_VOID>,<&CLK_VOID>,<&CLK_VOID>,<&CLK_VOID>,<&CLK_VOID>,<&CLK_VOID>;
    reg = <REG_CKG_SC_PIXEL_BASE 0x4>;
    mux-shift = <2>;  //2+REG_CKG_SC_PIXEL_OFFSET
    mux-width = <4>;
    gate-shift = <0>;  //0+REG_CKG_SC_PIXEL_OFFSET
#ifdef CONFIG_CAM_CLK
        ignore = <1>;
#endif
    auto-enable = <1>;
};

CLK_sata_pm: CLK_sata_pm {
    #clock-cells = <0>;
    compatible = "sstar,composite-clock";
    clocks = <&CLK_mpll_216m_div2>,<&CLK_xtali_12m>,<&CLK_xtali_24m>,<&CLK_mpll_123m>;
    reg = <REG_CKG_SATA_PM_BASE 0x4>;
    mux-shift = <10>;  //2+REG_CKG_SATA_PM_OFFSET
    mux-width = <2>;
    gate-shift = <8>;  //0+REG_CKG_SATA_PM_OFFSET
#ifdef CONFIG_CAM_CLK
        ignore = <1>;
#endif
};

CLK_sata_axi: CLK_sata_axi {
    #clock-cells = <0>;
    compatible = "sstar,composite-clock";
    clocks = <&CLK_utmi_240m>,<&CLK_mpll_288m>,<&CLK_VOID>,<&CLK_VOID>;
    reg = <REG_CKG_SATA_AXI_BASE 0x4>;
    mux-shift = <2>;  //2+REG_CKG_SATA_AXI_OFFSET
    mux-width = <2>;
    gate-shift = <0>;  //0+REG_CKG_SATA_AXI_OFFSET
#ifdef CONFIG_CAM_CLK
        ignore = <1>;
#endif
};

CLK_mipi_tx_dsi: CLK_mipi_tx_dsi {
    #clock-cells = <0>;
    compatible = "sstar,composite-clock";
    clocks = <&CLK_lpll_clk>,<&CLK_utmi_160m>,<&CLK_mpll_288m_div2>,<&CLK_mpll_216m_div2>,<&CLK_mpll_216m>,<&CLK_utmi_240m>,<&CLK_VOID>,<&CLK_VOID>;
    reg = <REG_CKG_MIPI_TX_DSI_BASE 0x4>;
    mux-shift = <2>;  //2+REG_CKG_MIPI_TX_DSI_OFFSET
    mux-width = <3>;
    gate-shift = <0>;  //0+REG_CKG_MIPI_TX_DSI_OFFSET
#ifdef CONFIG_CAM_CLK
        ignore = <1>;
#endif
    auto-enable = <1>;
};

CLK_csi_mac_lptx_top_i_m00: CLK_csi_mac_lptx_top_i_m00 {
    #clock-cells = <0>;
    compatible = "sstar,composite-clock";
    clocks = <&CLK_mpll_216m>,<&CLK_mpll_216m_div4>,<&CLK_mpll_172m>,<&CLK_mpll_288m_div2>,<&CLK_mpll_86m>,<&CLK_utmi_160m_div4>,<&CLK_VOID>,<&CLK_VOID>;
    reg = <REG_CKG_CSI_MAC_LPTX_TOP_I_M00_BASE 0x4>;
    mux-shift = <2>;  //2+REG_CKG_CSI_MAC_LPTX_TOP_I_M00_OFFSET
    mux-width = <3>;
    gate-shift = <0>;  //0+REG_CKG_CSI_MAC_LPTX_TOP_I_M00_OFFSET
#ifdef CONFIG_CAM_CLK
        ignore = <1>;
#endif
};

CLK_csi_mac_top_i_m00: CLK_csi_mac_top_i_m00 {
    #clock-cells = <0>;
    compatible = "sstar,composite-clock";
    clocks = <&CLK_mpll_216m>,<&CLK_mpll_216m_div4>,<&CLK_mpll_172m>,<&CLK_mpll_288m_div2>,<&CLK_mpll_86m>,<&CLK_utmi_160m_div4>,<&CLK_VOID>,<&CLK_VOID>;
    reg = <REG_CKG_CSI_MAC_TOP_I_M00_BASE 0x4>;
    mux-shift = <10>;  //2+REG_CKG_CSI_MAC_TOP_I_M00_OFFSET
    mux-width = <3>;
    gate-shift = <8>;  //0+REG_CKG_CSI_MAC_TOP_I_M00_OFFSET
};

CLK_ns_top_i_m00: CLK_ns_top_i_m00 {
    #clock-cells = <0>;
    compatible = "sstar,composite-clock";
    clocks = <&CLK_mpll_216m>,<&CLK_mpll_216m_div4>,<&CLK_mpll_172m>,<&CLK_mpll_288m_div2>,<&CLK_mpll_86m>,<&CLK_utmi_160m_div4>,<&CLK_VOID>,<&CLK_VOID>;
    reg = <REG_CKG_NS_TOP_I_M00_BASE 0x4>;
    mux-shift = <2>;  //2+REG_CKG_NS_TOP_I_M00_OFFSET
    mux-width = <3>;
    gate-shift = <0>;  //0+REG_CKG_NS_TOP_I_M00_OFFSET
};

CLK_csi_mac_lptx_top_i_m01: CLK_csi_mac_lptx_top_i_m01 {
    #clock-cells = <0>;
    compatible = "sstar,composite-clock";
    clocks = <&CLK_mpll_216m>,<&CLK_mpll_216m_div4>,<&CLK_mpll_172m>,<&CLK_mpll_288m_div2>,<&CLK_mpll_86m>,<&CLK_utmi_160m_div4>,<&CLK_VOID>,<&CLK_VOID>;
    reg = <REG_CKG_CSI_MAC_LPTX_TOP_I_M01_BASE 0x4>;
    mux-shift = <10>;  //2+REG_CKG_CSI_MAC_LPTX_TOP_I_M01_OFFSET
    mux-width = <3>;
    gate-shift = <8>;  //0+REG_CKG_CSI_MAC_LPTX_TOP_I_M01_OFFSET
};

CLK_csi_mac_top_i_m01: CLK_csi_mac_top_i_m01 {
    #clock-cells = <0>;
    compatible = "sstar,composite-clock";
    clocks = <&CLK_mpll_216m>,<&CLK_mpll_216m_div4>,<&CLK_mpll_172m>,<&CLK_mpll_288m_div2>,<&CLK_mpll_86m>,<&CLK_utmi_160m_div4>,<&CLK_VOID>,<&CLK_VOID>;
    reg = <REG_CKG_CSI_MAC_TOP_I_M01_BASE 0x4>;
    mux-shift = <2>;  //2+REG_CKG_CSI_MAC_TOP_I_M01_OFFSET
    mux-width = <3>;
    gate-shift = <0>;  //0+REG_CKG_CSI_MAC_TOP_I_M01_OFFSET
};

CLK_ns_top_i_m01: CLK_ns_top_i_m01 {
    #clock-cells = <0>;
    compatible = "sstar,composite-clock";
    clocks = <&CLK_mpll_216m>,<&CLK_mpll_216m_div4>,<&CLK_mpll_172m>,<&CLK_mpll_288m_div2>,<&CLK_mpll_86m>,<&CLK_utmi_160m_div4>,<&CLK_VOID>,<&CLK_VOID>;
    reg = <REG_CKG_NS_TOP_I_M01_BASE 0x4>;
    mux-shift = <10>;  //2+REG_CKG_NS_TOP_I_M01_OFFSET
    mux-width = <3>;
    gate-shift = <8>;  //0+REG_CKG_NS_TOP_I_M01_OFFSET
};

CLK_spi_pm: CLK_spi_pm {
    #clock-cells = <0>;
    compatible = "sstar,composite-clock";
    clocks = <&CLK_rtc_32k>,<&CLK_mpll_216m_div8>,<&CLK_mpll_144m_div4>,<&CLK_mpll_86m_div2>,<&CLK_mpll_216m_div4>,<&CLK_mpll_144m_div2>,<&CLK_mpll_86m>,<&CLK_mpll_216m_div2>,<&CLK_xtali_12m_div8>,<&CLK_xtali_12m_div12>,<&CLK_rtc_32k_div4>,<&CLK_xtali_12m_div16>,<&CLK_xtali_12m_div2>,<&CLK_xtali_12m_div4>,<&CLK_xtali_12m>,<&CLK_xtali_24m>;
    reg = <REG_CKG_SPI_BASE 0x4>;
    mux-shift = <2>;  //2+REG_CKG_SPI_OFFSET
    mux-width = <4>;
    gate-shift = <0>;  //0+REG_CKG_SPI_OFFSET
    glitch-shift = <6>;  //6+REG_CKG_SPI_OFFSET
    auto-enable = <1>;
};

CLK_pm_sleep: CLK_pm_sleep {
    #clock-cells = <0>;
    compatible = "sstar,composite-clock";
    clocks = <&CLK_xtali_12m>,<&CLK_rtc_32k>,<&CLK_xtali_12m_div8>,<&CLK_xtali_12m_div12>,<&CLK_rtc_32k_div4>,<&CLK_xtali_12m_div16>,<&CLK_xtali_12m_div2>,<&CLK_xtali_12m_div4>;
    reg = <REG_CKG_PM_SLEEP_BASE 0x4>;
    mux-shift = <12>;  //2+REG_CKG_PM_SLEEP_OFFSET
    mux-width = <3>;
    auto-enable = <1>;
};

CLK_pwm: CLK_pwm {
    #clock-cells = <0>;
    compatible = "sstar,composite-clock";
    clocks = <&CLK_xtali_12m>,<&CLK_rtc_32k>,<&CLK_xtali_12m_div8>,<&CLK_xtali_12m_div12>,<&CLK_rtc_32k_div4>,<&CLK_mpll_86m>,<&CLK_xtali_12m_div2>,<&CLK_xtali_12m_div4>;
    reg = <REG_CKG_PWM_BASE 0x4>;
    mux-shift = <12>;  //2+REG_CKG_PWM_OFFSET
    mux-width = <3>;
};

CLK_sar: CLK_sar {
    #clock-cells = <0>;
    compatible = "sstar,composite-clock";
    clocks = <&CLK_xtali_12m>,<&CLK_rtc_32k>,<&CLK_xtali_12m_div8>,<&CLK_xtali_12m_div12>,<&CLK_rtc_32k_div4>,<&CLK_xtali_12m_div16>,<&CLK_xtali_12m_div2>,<&CLK_xtali_12m_div4>;
    reg = <REG_CKG_SAR_BASE 0x4>;
    mux-shift = <7>;  //2+REG_CKG_SAR_OFFSET
    mux-width = <3>;
    gate-shift = <5>;  //0+REG_CKG_SAR_OFFSET
#ifdef CONFIG_CAM_CLK
        ignore = <1>;
#endif
    auto-enable = <1>;
};

CLK_rtc: CLK_rtc {
    #clock-cells = <0>;
    compatible = "sstar,composite-clock";
    clocks = <&CLK_xtali_12m>,<&CLK_rtc_32k>,<&CLK_VOID>,<&CLK_VOID>,<&CLK_VOID>,<&CLK_VOID>,<&CLK_VOID>,<&CLK_VOID>;
    reg = <REG_CKG_RTC_BASE 0x4>;
    mux-shift = <2>;  //2+REG_CKG_RTC_OFFSET
    mux-width = <3>;
    gate-shift = <0>;  //0+REG_CKG_RTC_OFFSET
};

CLK_ir: CLK_ir {
    #clock-cells = <0>;
    compatible = "sstar,composite-clock";
    clocks = <&CLK_xtali_12m>,<&CLK_rtc_32k>,<&CLK_xtali_12m_div8>,<&CLK_xtali_12m_div12>,<&CLK_rtc_32k_div4>,<&CLK_xtali_12m_div16>,<&CLK_xtali_12m_div2>,<&CLK_xtali_12m_div4>;
    reg = <REG_CKG_IR_BASE 0x4>;
    mux-shift = <7>;  //2+REG_CKG_IR_OFFSET
    mux-width = <3>;
    gate-shift = <5>;  //0+REG_CKG_IR_OFFSET
};

CLK_dac: CLK_dac {
    #clock-cells = <0>;
    compatible = "sstar,composite-clock";
    clocks = <&CLK_dac_in>,<&CLK_hdmi_p>,<&CLK_VOID>,<&CLK_VOID>;
    reg = <REG_CKG_DAC_BASE 0x4>;
    mux-shift = <2>;  //2+REG_CKG_DAC_OFFSET
    mux-width = <2>;
    gate-shift = <0>;  //0+REG_CKG_DAC_OFFSET
    auto-enable = <1>;
};
 
CLK_emac_rx: CLK_emac_rx {
    #clock-cells = <0>;
    compatible = "sstar,composite-clock";
    clocks = <&CLK_emac_rx_in_buf>,<&CLK_emac_mmi_rx_buf>,<&CLK_VOID>,<&CLK_VOID>;
    reg = <REG_CKG_EMAC_RX_BASE 0x4>;
    mux-shift = <2>;  //2+REG_CKG_EMAC_RX_OFFSET
    mux-width = <2>;
    gate-shift = <0>;  //0+REG_CKG_EMAC_RX_OFFSET
#ifdef CONFIG_CAM_CLK
    ignore = <1>;
#endif
};
 
CLK_emac_rx_ref: CLK_emac_rx_ref {
    #clock-cells = <0>;
    compatible = "sstar,composite-clock";
    clocks = <&CLK_emac_tx_ref_pad_buf>,<&CLK_VOID>,<&CLK_VOID>,<&CLK_VOID>;
    reg = <REG_CKG_EMAC_RX_REF_BASE 0x4>;
    mux-shift = <10>;  //2+REG_CKG_EMAC_RX_REF_OFFSET
    mux-width = <2>;
    gate-shift = <8>;  //0+REG_CKG_EMAC_RX_REF_OFFSET
#ifdef CONFIG_CAM_CLK
    ignore = <1>;
#endif
};
 
CLK_emac_tx: CLK_emac_tx {
    #clock-cells = <0>;
    compatible = "sstar,composite-clock";
    clocks = <&CLK_emac_tx_in_buf>,<&CLK_emac_mmi_tx_buf>,<&CLK_VOID>,<&CLK_VOID>;
    reg = <REG_CKG_EMAC_TX_BASE 0x4>;
    mux-shift = <2>;  //2+REG_CKG_EMAC_TX_OFFSET
    mux-width = <2>;
    gate-shift = <0>;  //0+REG_CKG_EMAC_TX_OFFSET
#ifdef CONFIG_CAM_CLK
    ignore = <1>;
#endif
};
 
CLK_emac_tx_ref: CLK_emac_tx_ref {
    #clock-cells = <0>;
    compatible = "sstar,composite-clock";
    clocks = <&CLK_emac_tx_ref_pad_buf>,<&CLK_VOID>,<&CLK_VOID>,<&CLK_VOID>;
    reg = <REG_CKG_EMAC_TX_REF_BASE 0x4>;
    mux-shift = <10>;  //2+REG_CKG_EMAC_TX_REF_OFFSET
    mux-width = <2>;
    gate-shift = <8>;  //0+REG_CKG_EMAC_TX_REF_OFFSET
#ifdef CONFIG_CAM_CLK
    ignore = <1>;
#endif
};
 
CLK_gop0_psram: CLK_gop0_psram {
    #clock-cells = <0>;
    compatible = "sstar,composite-clock";
    clocks = <&CLK_odclk_live_p>,<&CLK_miu_gop0_p>,<&CLK_VOID>,<&CLK_VOID>;
    reg = <REG_CKG_GOP0_PSRAM_BASE 0x4>;
    mux-shift = <2>;  //2+REG_CKG_GOP0_PSRAM_OFFSET
    mux-width = <2>;
    gate-shift = <0>;  //0+REG_CKG_GOP0_PSRAM_OFFSET
#ifdef CONFIG_CAM_CLK
    ignore = <1>;
#endif
    auto-enable = <1>;
};
 
CLK_gop1_psram: CLK_gop1_psram {
    #clock-cells = <0>;
    compatible = "sstar,composite-clock";
    clocks = <&CLK_odclk_live_p>,<&CLK_miu_gop1_p>,<&CLK_VOID>,<&CLK_VOID>;
    reg = <REG_CKG_GOP1_PSRAM_BASE 0x4>;
    mux-shift = <6>;  //2+REG_CKG_GOP1_PSRAM_OFFSET
    mux-width = <2>;
    gate-shift = <4>;  //0+REG_CKG_GOP1_PSRAM_OFFSET
#ifdef CONFIG_CAM_CLK
    ignore = <1>;
#endif
    auto-enable = <1>;
};
 
CLK_hdmi: CLK_hdmi {
    #clock-cells = <0>;
    compatible = "sstar,composite-clock";
    clocks = <&CLK_hdmi_p>,<&CLK_sc_pixel_p>,<&CLK_VOID>,<&CLK_VOID>;
    reg = <REG_CKG_HDMI_BASE 0x4>;
    mux-shift = <2>;  //2+REG_CKG_HDMI_OFFSET
    mux-width = <2>;
    gate-shift = <0>;  //0+REG_CKG_HDMI_OFFSET
#ifdef CONFIG_CAM_CLK
    ignore = <1>;
#endif
    auto-enable = <1>;
};
 
CLK_imi: CLK_imi {
    #clock-cells = <0>;
    compatible = "sstar,composite-clock";
    clocks = <&CLK_miu_p>,<&CLK_VOID>;
    reg = <REG_CKG_IMI_BASE 0x4>;
    mux-shift = <2>;  //2+REG_CKG_IMI_OFFSET
    mux-width = <1>;
    gate-shift = <0>;  //0+REG_CKG_IMI_OFFSET
#ifdef CONFIG_CAM_CLK
    ignore = <1>;
#endif
    auto-enable = <1>;
};
 
CLK_lcd: CLK_lcd {
    #clock-cells = <0>;
    compatible = "sstar,composite-clock";
    clocks = <&CLK_sc_pixel_p>,<&CLK_hdmi_p>,<&CLK_VOID>,<&CLK_VOID>;
    reg = <REG_CKG_LCD_BASE 0x4>;
    mux-shift = <2>;  //2+REG_CKG_LCD_OFFSET
    mux-width = <2>;
    gate-shift = <0>;  //0+REG_CKG_LCD_OFFSET
#ifdef CONFIG_CAM_CLK
    ignore = <1>;
#endif
    auto-enable = <1>;
};
 
CLK_mipi_tx_dsi_apb: CLK_mipi_tx_dsi_apb {
    #clock-cells = <0>;
    compatible = "sstar,composite-clock";
    clocks = <&CLK_mcu_p>,<&CLK_mipi_tx_dsi_p>,<&CLK_VOID>,<&CLK_VOID>;
    reg = <REG_CKG_MIPI_TX_DSI_APB_BASE 0x4>;
    mux-shift = <2>;  //2+REG_CKG_MIPI_TX_DSI_APB_OFFSET
    mux-width = <2>;
    gate-shift = <0>;  //0+REG_CKG_MIPI_TX_DSI_APB_OFFSET
#ifdef CONFIG_CAM_CLK
    ignore = <1>;
#endif
    auto-enable = <1>;
};
 
CLK_sd: CLK_sd {
    #clock-cells = <0>;
    compatible = "sstar,composite-clock";
    clocks = <&CLK_miu_sc_gp_p_inv>,<&CLK_pad_sdio_clk_mux>,<&CLK_VOID>,<&CLK_VOID>;
    reg = <REG_CKG_SD_BASE 0x4>;
    mux-shift = <3>;  //3+REG_CKG_SD_OFFSET
    mux-width = <2>;
    gate-shift = <0>;  //0+REG_CKG_SD_OFFSET
#ifdef CONFIG_CAM_CLK
    ignore = <1>;
#endif
};


CLK_eth_buf: CLK_eth_buf {
    #clock-cells = <0>;
    compatible = "fixed-clock";
    clock-frequency = <1>;
};

CLK_rmii_buf: CLK_rmii_buf {
    #clock-cells = <0>;
    compatible = "fixed-clock";
    clock-frequency = <1>;
};

CLK_emac_tx: CLK_emac_tx {
    #clock-cells = <0>;
    compatible = "sstar,composite-clock";
    clocks = <&CLK_eth_buf>,<&CLK_rmii_buf>;
    reg = <REG_CKG_EMAC_TX_BASE 0x4>;
    mux-shift = <2>;  //2+REG_CKG_EMAC_TX_OFFSET
    mux-width = <1>;
    gate-shift = <0>;  //0+REG_CKG_EMAC_TX_OFFSET
#ifdef CONFIG_CAM_CLK
    ignore = <1>;
#endif
};

CLK_emac_rx: CLK_emac_rx {
    #clock-cells = <0>;
    compatible = "sstar,composite-clock";
    clocks = <&CLK_eth_buf>,<&CLK_rmii_buf>;
    reg = <REG_CKG_EMAC_RX_BASE 0x4>;
    mux-shift = <2>;  //2+REG_CKG_EMAC_RX_OFFSET
    mux-width = <1>;
    gate-shift = <0>;  //0+REG_CKG_EMAC_RX_OFFSET
#ifdef CONFIG_CAM_CLK
    ignore = <1>;
#endif
};

CLK_emac_tx_ref: CLK_emac_tx_ref {
    #clock-cells = <0>;
    compatible = "sstar,composite-clock";
    clocks = <&CLK_rmii_buf>,<&CLK_VOID>;
    reg = <REG_CKG_EMAC_TX_REF_BASE 0x4>;
    mux-shift = <10>;  //2+REG_CKG_EMAC_TX_REF_OFFSET
    mux-width = <1>;
    gate-shift = <8>;  //0+REG_CKG_EMAC_TX_REF_OFFSET
};

CLK_emac_rx_ref: CLK_emac_rx_ref {
    #clock-cells = <0>;
    compatible = "sstar,composite-clock";
    clocks = <&CLK_rmii_buf>,<&CLK_VOID>;
    reg = <REG_CKG_EMAC_RX_REF_BASE 0x4>;
    mux-shift = <10>;  //2+REG_CKG_EMAC_RX_REF_OFFSET
    mux-width = <1>;
    gate-shift = <8>;  //0+REG_CKG_EMAC_RX_REF_OFFSET
};


/*fake*/
CLK_cpupll_clk: CLK_cpupll_clk {
    #clock-cells = <0>;
    compatible = "sstar,complex-clock";
    clocks = <&CLK_mpll_432m>;
};

usclk: usclk {
    compatible = "usclk";
    clocks = <&CLK_VOID>, <&CLK_aesdma>, <&CLK_armpll_37p125m>, <&CLK_bdma>, <&CLK_bdma2>, <&CLK_bdma3>, <&CLK_bist>, <&CLK_bist_isp_gp>, <&CLK_bist_mcu>, <&CLK_bist_sc_gp>, <&CLK_boot>, <&CLK_csi_mac_lptx_top_i_m00>, <&CLK_csi_mac_lptx_top_i_m01>, <&CLK_csi_mac_top_i_m00>, <&CLK_csi_mac_top_i_m01>, <&CLK_ddr_syn>, <&CLK_dip>, <&CLK_disp_216>, <&CLK_disp_432>, <&CLK_emac_ahb>, <&CLK_emac_testrx125_in_lan>, <&CLK_fclk1>, <&CLK_fuart>, <&CLK_fuart0_synth_in>, <&CLK_fuart0_synth_out>, <&CLK_ge>, <&CLK_ir>, <&CLK_isp>, <&CLK_jpe>, <&CLK_keypad>, <&CLK_live>, <&CLK_live_c>, <&CLK_lpll_clk>, <&CLK_lpll_clk_div2>, <&CLK_lpll_clk_div4>, <&CLK_lpll_clk_div8>, <&CLK_mcu>, <&CLK_mcu_p>, <&CLK_miic0>, <&CLK_miic1>, <&CLK_mipi_tx_dsi>, <&CLK_miu_p>, <&CLK_miu_rec>, <&CLK_mop>, <&CLK_mpll_123m>, <&CLK_mpll_123m_div2>, <&CLK_mpll_144m>, <&CLK_mpll_144m_div2>, <&CLK_mpll_144m_div4>, <&CLK_mpll_172m>, <&CLK_mpll_216m>, <&CLK_mpll_216m_div2>, <&CLK_mpll_216m_div4>, <&CLK_mpll_216m_div8>, <&CLK_mpll_288m>, <&CLK_mpll_288m_div2>, <&CLK_mpll_288m_div32>, <&CLK_mpll_288m_div4>, <&CLK_mpll_288m_div8>, <&CLK_mpll_432m>, <&CLK_mpll_86m>, <&CLK_mpll_86m_div16>, <&CLK_mpll_86m_div2>, <&CLK_mpll_86m_div4>, <&CLK_mspi0>, <&CLK_mspi1>, <&CLK_ns_top_i_m00>, <&CLK_ns_top_i_m01>, <&CLK_pm_sleep>, <&CLK_pspi0>, <&CLK_pspi1>, <&CLK_pwm>, <&CLK_pwr_ctl>, <&CLK_riubrdg>, <&CLK_rtc>, <&CLK_rtc_32k>, <&CLK_rtc_32k_div4>, <&CLK_sar>, <&CLK_sata_axi>, <&CLK_sata_phy_108>, <&CLK_sata_phy_432>, <&CLK_sata_pm>, <&CLK_sc_pixel>, <&CLK_sdio>, <&CLK_spi>, <&CLK_spi_pm>, <&CLK_spi_synth_pll>, <&CLK_sr00_mclk>, <&CLK_sr01_mclk>, <&CLK_uart0>, <&CLK_uart1>, <&CLK_uart2>, <&CLK_upll_320m>, <&CLK_upll_384m>, <&CLK_upll_synth>, <&CLK_utmi_160m>, <&CLK_utmi_160m_div4>, <&CLK_utmi_160m_div5>, <&CLK_utmi_160m_div8>, <&CLK_utmi_192m>, <&CLK_utmi_192m_div4>, <&CLK_utmi_240m>, <&CLK_utmi_480m>, <&CLK_xtali>, <&CLK_xtali_12m>, <&CLK_xtali_12m_div12>, <&CLK_xtali_12m_div128>, <&CLK_xtali_12m_div16>, <&CLK_xtali_12m_div2>, <&CLK_xtali_12m_div4>, <&CLK_xtali_12m_div40>, <&CLK_xtali_12m_div64>, <&CLK_xtali_12m_div8>, <&CLK_xtali_24m>, <&CLK_xtali_sc_gp>;
    clock-count = <115>;
};

